# SF32LB56x register map
File version: 1.0
CPU: CM33 r0p1, little endian, MPU, FPU, 3 interrupt priority bits
Registers are 32-bit, read-write, reset 0x0 unless marked. A register's access mark holds for its fields unless they carry their own. Offsets are from the block's base; [hi:lo] are bit positions; {n}, {i} and the like mark numbered series; 'fields as' and 'values as' point back to an identical list.

## AUDCODEC_HP
Base 0x40026000
0x00 ID reset 0xC0DEC000
  [31:0] FUNC — function id
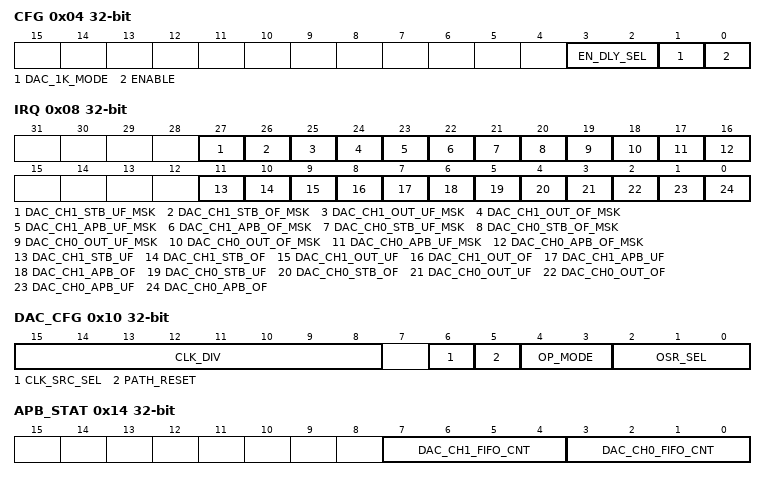
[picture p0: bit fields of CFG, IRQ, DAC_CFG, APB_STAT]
0x04 CFG
  [3:2] EN_DLY_SEL — codec enable delay count 0: no delay 1: 32 pclk 2: 64 pclk 3: 128 pclk
  [1] DAC_1K_MODE — codec dac sine 1k mode
  [0] ENABLE — codec enable
0x08 IRQ
  [27] DAC_CH1_STB_UF_MSK — interrupt mask. 0: mask the interrupt.
  [26] DAC_CH1_STB_OF_MSK — interrupt mask. 0: mask the interrupt.
  [25] DAC_CH1_OUT_UF_MSK — interrupt mask. 0: mask the interrupt.
  [24] DAC_CH1_OUT_OF_MSK — interrupt mask. 0: mask the interrupt.
  [23] DAC_CH1_APB_UF_MSK — interrupt mask. 0: mask the interrupt.
  [22] DAC_CH1_APB_OF_MSK — interrupt mask. 0: mask the interrupt.
  [21] DAC_CH0_STB_UF_MSK — interrupt mask. 0: mask the interrupt.
  [20] DAC_CH0_STB_OF_MSK — interrupt mask. 0: mask the interrupt.
  [19] DAC_CH0_OUT_UF_MSK — interrupt mask. 0: mask the interrupt.
  [18] DAC_CH0_OUT_OF_MSK — interrupt mask. 0: mask the interrupt.
  [17] DAC_CH0_APB_UF_MSK — interrupt mask. 0: mask the interrupt.
  [16] DAC_CH0_APB_OF_MSK — interrupt mask. 0: mask the interrupt.
  [11] DAC_CH1_STB_UF — dac ch1 input stb fifo overflow interrupt status. Write 1 to clear.
  [10] DAC_CH1_STB_OF — dac ch1 input stb fifo overflow interrupt status. Write 1 to clear.
  [9] DAC_CH1_OUT_UF — dac ch1 output fifo underflow interrupt status. Write 1 to clear.
  [8] DAC_CH1_OUT_OF — dac ch1 output fifo overflow interrupt status. Write 1 to clear.
  [7] DAC_CH1_APB_UF — dac ch1 apb fifo underflow interrupt status. Write 1 to clear.
  [6] DAC_CH1_APB_OF — dac ch1 apb fifo overflow interrupt status. Write 1 to clear.
  [5] DAC_CH0_STB_UF — dac ch0 input stb fifo overflow interrupt status. Write 1 to clear.
  [4] DAC_CH0_STB_OF — dac ch0 input stb fifo overflow interrupt status. Write 1 to clear.
  [3] DAC_CH0_OUT_UF — dac ch0 output fifo underflow interrupt status. Write 1 to clear.
  [2] DAC_CH0_OUT_OF — dac ch0 output fifo overflow interrupt status. Write 1 to clear.
  [1] DAC_CH0_APB_UF — dac ch0 apb fifo underflow interrupt status. Write 1 to clear.
  [0] DAC_CH0_APB_OF — dac ch0 apb fifo overflow interrupt status. Write 1 to clear.
0x10 DAC_CFG
  [15:8] CLK_DIV — dac clock divider
  [6] CLK_SRC_SEL — dac clock source select 1: pll 0: xtal
  [5] PATH_RESET — dac path reset, set 1 to reset dac path
  [4:3] OP_MODE — dac operation mode 2'h0: normal mode: send dac data through tx interface 2'h1: apb mode: send dac data out through apb interface 2'h2, 2'h3: reserved
  [2:0] OSR_SEL — DAC oversample rate 3'b000: 100 3'b001: 150 3'b010: 300 3'b100: 64 3'b101: 128 3'b110: 256 other: reserved
0x14 APB_STAT
  [7:4] DAC_CH1_FIFO_CNT, [3:0] DAC_CH0_FIFO_CNT
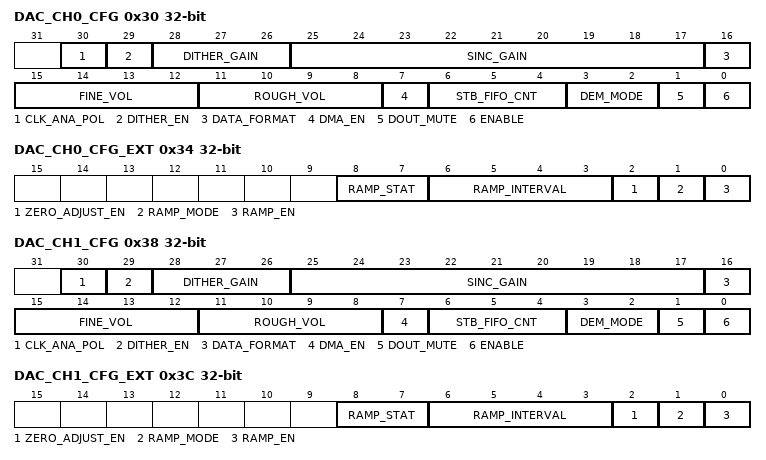
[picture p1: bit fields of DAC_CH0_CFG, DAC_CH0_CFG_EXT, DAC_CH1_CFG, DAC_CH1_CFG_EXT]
0x30 DAC_CH0_CFG
  [30] CLK_ANA_POL — analog dac clock polarity
  [29] DITHER_EN — sdm dither enable
  [28:26] DITHER_GAIN — sdm dither gain
  [25:17] SINC_GAIN — dac sinc filter gain
  [16] DATA_FORMAT — dac data format 1: 16-bit 0: 24-bit this bit only affect the data format accessed by apb interface. For 24-bit, every 24-bit data occupied 32-bit word. Bit[31:24] are zeros. For 16-bit mode, every 32-bit word contains two 16-bit audio data{D1, D0}
  [15:12] FINE_VOL — dac fine volume control range from 0dB to 6dB step is 0.5dB 4'h0: 0dB 4'h1: 0.5dB ...... 4'hb: 5.5dB 4'hc, 4'hd, 4'he, 4'hf: mute
  [11:8] ROUGH_VOL — dac rough volume control range from -36dB to 54dB step is 6dB 4'h0: -36dB 4'h1: -30dB ...... 4'h6: 0dB ...... 4'he: 48dB 4'hf: 54dB
  [7] DMA_EN — dma interface enable in apb mode 1: enable dac ch0 dma request interface 0: disable dac ch0 dma request interface
  [6:4] STB_FIFO_CNT — dac input stb fifo cnt
  [3:2] DEM_MODE — dem output mode 2'h0: no shift for dem output 2'h1: shift dem output incrementally 2'h2: shift dem output according to input 2'h3: reserved
  [1] DOUT_MUTE — dac output mute, set 1 to mute the output
  [0] ENABLE — dac channel enable
0x34 DAC_CH0_CFG_EXT
  [8:7] RAMP_STAT — ramp module status
  [6:3] RAMP_INTERVAL — volume ramp interval.
  [2] ZERO_ADJUST_EN — enable volume adjustment during 0 volume cross.
  [1] RAMP_MODE — volume ramp mode: 1: slowly ramp to target volume. Step is 0.5db 0: directly ramp to target volume.
  [0] RAMP_EN — volume ramp enable
0x38 DAC_CH1_CFG
  fields as DAC_CH0_CFG
0x3C DAC_CH1_CFG_EXT
  fields as DAC_CH0_CFG_EXT
0x50 DAC_CH0_ENTRY
  [31:0] DATA — dac channel0 data input
0x54 DAC_CH1_ENTRY
  [31:0] DATA — dac channel0 data input
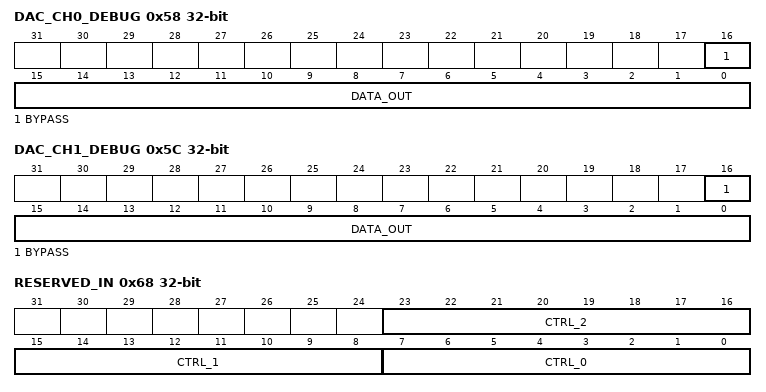
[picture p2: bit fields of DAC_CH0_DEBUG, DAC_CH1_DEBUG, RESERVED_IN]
0x58 DAC_CH0_DEBUG
  [16] BYPASS — debug bypass mode
  [15:0] DATA_OUT — debug dac output
0x5C DAC_CH1_DEBUG
  [16] BYPASS — debug bypass mode
  [15:0] DATA_OUT — debug dac output
0x60 DAC_CH0_DC
  [23:0] OFFSET — dac ch0 dc offset
0x64 DAC_CH1_DC
  [23:0] OFFSET — dac ch1 dc offset
0x68 RESERVED_IN
  [23:16] CTRL_2 — reserved control 2
  [15:8] CTRL_1 — reserved control 1
  [7:0] CTRL_0 — reserved control 0
0x6C RESERVED_OUT
  [7:0] STAT — reserved status
